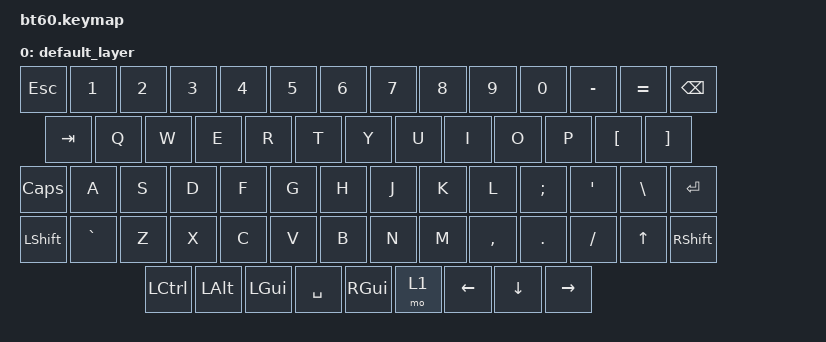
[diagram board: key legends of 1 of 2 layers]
#include <behaviors.dtsi>
#include <dt-bindings/zmk/keys.h>
#include <dt-bindings/zmk/bt.h>
#include <dt-bindings/zmk/rgb.h>
#include <dt-bindings/zmk/backlight.h>

/ {
	keymap {
		compatible = "zmk,keymap";

		default_layer {
				// .--------------------------------------------------------------------------------------------.
				// | ESC |  1  |  2  |  3  |  4  |  5  |  6  |  7  |  8  |  9  |  0  |  -  |  =  |    BKSP      |
				// | TAB  |  Q  |  W  |  E  |  R  |  T  |  Y  |  U  |  I  |  O  |  P  |  [  |  ]  |             |
				// | CAPS  |  A  |  S  |  D  |  F  |  G  |  H  |  J  |  K  |  L  |  ;  |  '  |  \  |   ENTER    |
				// | SFT |  ~  |  Z  |  X  |  C  |  V  |  B  |  N  |  M  |  ,  |  .  |     /    | U_ARR | R_SFT |
				// | CTL | ALT | OS  |              SPACE                   | OS  |  1  | L_ARR | D_ARR | R_ARR |
				// '--------------------------------------------------------------------------------------------'
			bindings = <
				&kp ESC &kp N1 &kp N2 &kp N3 &kp N4 &kp N5 &kp N6 &kp N7 &kp  N8   &kp  N9 &kp  N0  &kp MINUS &kp EQUAL &kp BSPC
				&kp TAB  &kp Q  &kp W  &kp E  &kp R  &kp T  &kp Y  &kp U  &kp  I    &kp  O  &kp  P   &kp LBKT &kp RBKT
				&kp CAPS  &kp A  &kp S  &kp D  &kp F  &kp G  &kp H  &kp J  &kp  K    &kp  L  &kp SEMI &kp SQT &kp BACKSLASH  &kp RET
				&kp LSHFT &kp GRAVE &kp Z  &kp X  &kp C  &kp V  &kp B  &kp N  &kp M  &kp COMMA &kp DOT     &kp FSLH      &kp UP_ARROW   &kp RIGHT_SHIFT
				&kp LCTRL &kp LALT &kp LGUI            &kp SPACE                          &kp RGUI  &mo 1 &kp LEFT_ARROW &kp DOWN_ARROW &kp RIGHT_ARROW
			>;
			sensor-bindings = <&inc_dec_kp C_VOL_UP C_VOL_DN>;
		};
		raise {
			bindings = <
				&bt BT_CLR &kp F1 &kp F2 &kp F3 &kp F4 &kp F5 &kp F6 &kp F7 &kp F8 &kp F9 &kp F10 &kp K_VOL_DN &kp K_VOL_UP &kp F10
				&trans &trans &kp UP &trans &trans &trans &trans &trans &trans &kp UP_ARROW &trans &kp K_BRI_DN &kp K_BRI_UP
				&kp CAPS    &kp LEFT &kp DOWN &kp RIGHT &trans &trans &trans &kp LEFT_ARROW &kp DOWN_ARROW &kp RIGHT_ARROW  &trans &kp F7 &kp F9 &kp F8
				&kp C_PREV &kp C_VOL_DN &kp C_VOL_UP &kp C_MUTE &bl BL_INC &bl BL_DEC &trans &trans &trans &rgb_ug RGB_TOG &kp END &kp PG_DN  &bl BL_TOG
				&bt BT_PRV &bt BT_NXT  &trans              &trans                            &trans   &trans   &trans &bt BT_CLR
			>;
			sensor-bindings = <&inc_dec_kp C_VOL_UP C_VOL_DN>;
		};
	};
};
